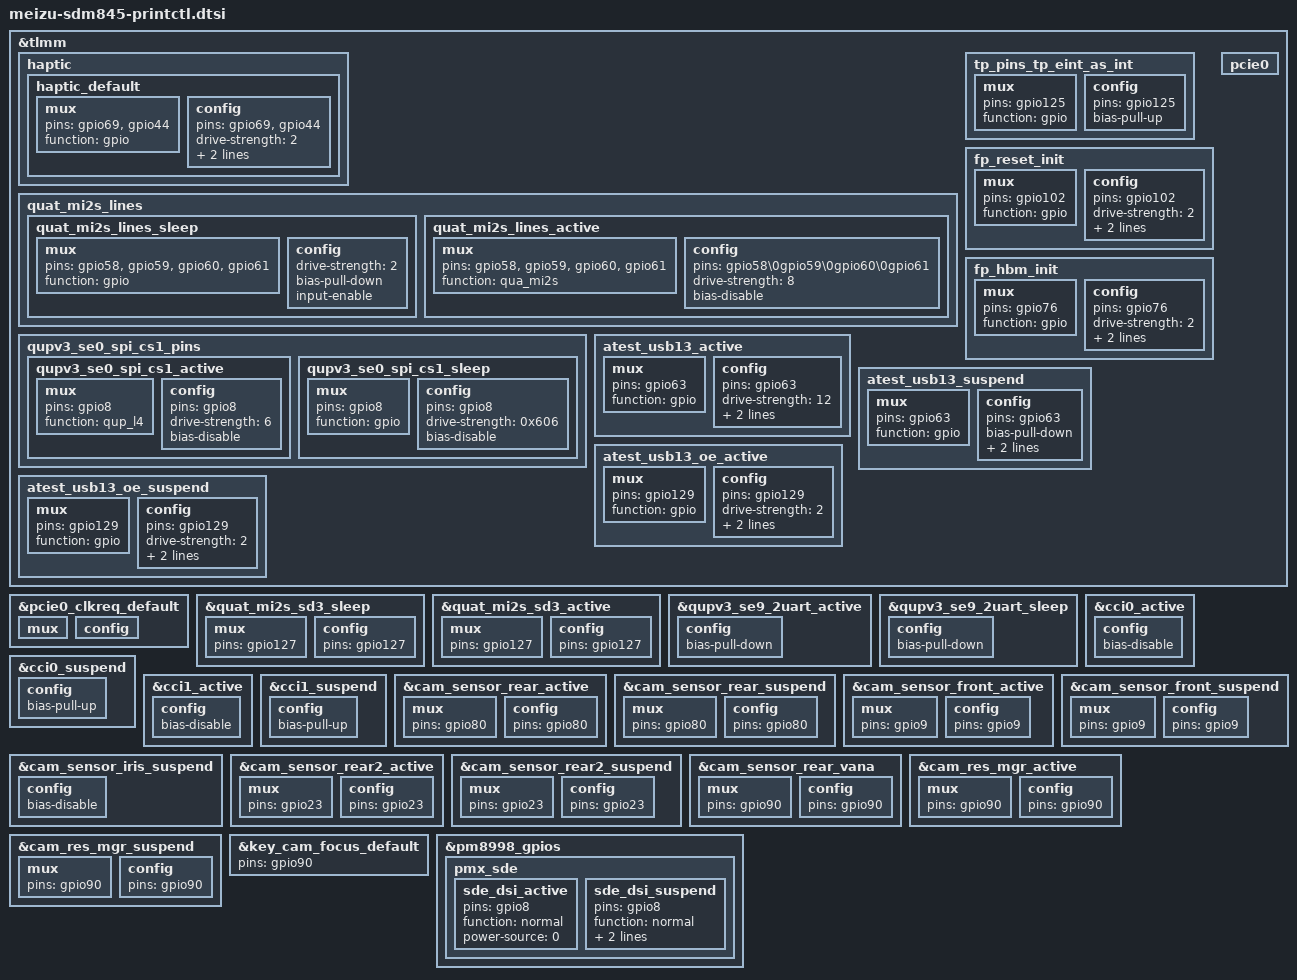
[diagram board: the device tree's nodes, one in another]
&tlmm {
	/delete-node/ storage_cd;
	/delete-node/ spkr_i2s_clk_pin;
	/delete-node/ pmx_sde;
	/delete-node/ pmx_ts_int_active;
	/delete-node/ pmx_ts_int_suspend;
	/delete-node/ pmx_ts_reset_active;
	/delete-node/ pmx_ts_reset_suspend;
	/delete-node/ pmx_ts_release;
	/delete-node/ ts_mux;
	/delete-node/ ext_bridge_mux;
	/delete-node/ ap2mdm;
	/delete-node/ mdm2ap;

	haptic {
		haptic_default: haptic_default {
			mux {
				pins = "gpio69", "gpio44";
				function = "gpio";
			};

			config {
				pins = "gpio69", "gpio44";
				drive-strength = <2>;
				bias-pull-up;
				input-enable;
			};
		};
	};

	quat_mi2s_lines {
		quat_mi2s_lines_sleep: quat_mi2s_lines_sleep {
			mux {
				pins = "gpio58", "gpio59", "gpio60", "gpio61";
				function = "gpio";
			};

			config {
				drive-strength = <2>;
				bias-pull-down;
				input-enable;
			};
		};

		quat_mi2s_lines_active: quat_mi2s_lines_active {
			mux {
				pins = "gpio58", "gpio59", "gpio60", "gpio61";
				function = "qua_mi2s";
			};

			config {
				pins = "gpio58", "gpio59", "gpio60", "gpio61";
				drive-strength = <8>;
				bias-disable;
			};
		};
	};

	qupv3_se0_spi_cs1_pins {
		qupv3_se0_spi_cs1_active: qupv3_se0_spi_cs1_active {
			mux {
				pins = "gpio8";
				function = "qup_l4";
			};

			config {
				pins = "gpio8";
				drive-strength = <6>;
				bias-disable;
			};
		};

		qupv3_se0_spi_cs1_sleep: qupv3_se0_spi_cs1_sleep {
			mux {
				pins = "gpio8";
				function = "gpio";
			};

			config {
				pins = "gpio8";
				drive-strength = <0x606>;
				bias-disable;
			};
		};
	};

	tp_pins_tp_eint_as_int: tp_pins_tp_eint_as_int {
		mux {
			pins = "gpio125";
			function = "gpio";
		};

		config {
			pins = "gpio125";
			bias-pull-up;
		};
	};

	fp_reset_init: fp_reset_init {
		mux {
			pins = "gpio102";
			function = "gpio";
		};

		config {
			pins = "gpio102";
			drive-strength = <2>;
			bias-disable;
			output-low;
		};
	};

	fp_hbm_init: fp_hbm_init {
		mux {
			pins = "gpio76";
			function = "gpio";
        };

		config {
			pins = "gpio76";
			drive-strength = <2>;
			bias-disable;
			output-low;
		};
	};

	atest_usb13_active: atest_usb13_active {
		mux {
			pins = "gpio63";
			function = "gpio";
		};

		config {
			pins = "gpio63";
			drive-strength = <12>;
			bias-pull-up;
			output-high;
		};
	};

	atest_usb13_suspend: atest_usb13_suspend {
		mux {
			pins = "gpio63";
			function = "gpio";
		};

		config {
			pins = "gpio63";
			bias-pull-down;
			drive-strength = <2>;
			output-low;
		};
	};

	atest_usb13_oe_active: atest_usb13_oe_active {
		mux {
			pins = "gpio129";
			function = "gpio";
		};

		config {
			pins = "gpio129";
			drive-strength = <2>;
			bias-pull-down;
			output-low;
		};
	};

	atest_usb13_oe_suspend: atest_usb13_oe_suspend {
		mux {
			pins = "gpio129";
			function = "gpio";
		};

		config {
			pins = "gpio129";
			drive-strength = <2>;
			bias-pull-up;
			output-high;
		};
	};

	quat_mi2s_lines {
		quat_mi2s_lines_sleep: quat_mi2s_lines_sleep {
			mux {
				pins = "gpio58", "gpio59", "gpio60", "gpio61";
				function = "gpio";
			};

			config {
				drive-strength = <2>;
				bias-pull-down;
				input-enable;
			};
		};

		quat_mi2s_lines_active: quat_mi2s_lines_active {
			mux {
				pins = "gpio58", "gpio59", "gpio60", "gpio61";
				function = "qua_mi2s";
			};

			config {
				pins = "gpio58\0gpio59\0gpio60\0gpio61";
				drive-strength = <8>;
				bias-disable;
			};
		};
	};
};

&tlmm {
	pcie0 {
		/delete-node/ pcie0_3v3_on;
		/delete-node/ pcie0_1v5_on;
	};
};

&pcie0_clkreq_default {
	mux {
		/delete-property/ pins;
		/delete-property/ function;
	};

	config {
		/delete-property/ pins;
		/delete-property/ drive-strength;
		/delete-property/ bias-pull-up;
	};
};

&quat_mi2s_sd3_sleep {
	mux {
		pins = "gpio127";
	};

	config {
		pins = "gpio127";
	};
};

&quat_mi2s_sd3_active {
	mux {
		pins = "gpio127";
	};

	config {
		pins = "gpio127";
	};
};

&qupv3_se9_2uart_active {
	config {
		/delete-property/ bias-disable;
		bias-pull-down;
	};
};

&qupv3_se9_2uart_sleep {
	config {
		/delete-property/ bias-disable;
		bias-pull-down;
	};
};

&cci0_active {
	config {
		/delete-property/ bias-pull-up;
		bias-disable;
	};
};

&cci0_suspend {
	config {
		/delete-property/ bias-pull-down;
		bias-pull-up;
	};
};

&cci1_active {
	config {
		/delete-property/ bias-pull-up;
		bias-disable;
	};
};

&cci1_suspend {
	config {
		/delete-property/ bias-pull-down;
		bias-pull-up;
	};
};

&cam_sensor_rear_active {
	mux {
		pins = "gpio80";
	};

	config {
		pins = "gpio80";
	};
};

&cam_sensor_rear_suspend {
	mux {
		pins = "gpio80";
	};

	config {
		pins = "gpio80";
	};
};

&cam_sensor_front_active {
	mux {
		pins = "gpio9";
	};

	config {
		pins = "gpio9";
	};
};

&cam_sensor_front_suspend {
	mux {
		pins = "gpio9";
	};

	config {
		pins = "gpio9";
	};
};

&cam_sensor_iris_suspend {
	config {
		/delete-property/ bias-pull-down;
		bias-disable;
	};
};

&cam_sensor_rear2_active {
	mux {
		pins = "gpio23";
	};

	config {
		pins = "gpio23";
	};
};

&cam_sensor_rear2_suspend {
	mux {
		pins = "gpio23";
	};

	config {
		pins = "gpio23";
	};
};

&cam_sensor_rear_vana {
	mux {
		pins = "gpio90";
	};

	config {
		pins = "gpio90";
	};
};

&cam_res_mgr_active {
	mux {
		pins = "gpio90";
	};

	config {
		pins = "gpio90";
	};
};

&cam_res_mgr_suspend {
	mux {
		pins = "gpio90";
	};

	config {
		pins = "gpio90";
	};
};

&key_cam_focus_default {
	pins = "gpio90";
};

&pm8998_gpios {
	/delete-node/ led_bt;
	/delete-node/ led_wifi;
	/delete-node/ camera_rear_avdd_en;

	pmx_sde {
		sde_dsi_active: sde_dsi_active {
			pins = "gpio8";
			function = "normal";
			power-source = <0>;
		};

		sde_dsi_suspend: sde_dsi_suspend {
			pins = "gpio8";
			function = "normal";
			power-source = <0>;
			bias-pull-down;
		};
	};
};
